# STM32WL3xx register map
File version: 1.0
Registers are 32-bit, read-write, reset 0x0 unless marked. A register's access mark holds for its fields unless they carry their own. Offsets are from the block's base; [hi:lo] are bit positions.

## MR_SUBG_GLOB_STATUS — MR_SUBG Global Status
Base 0x49000600
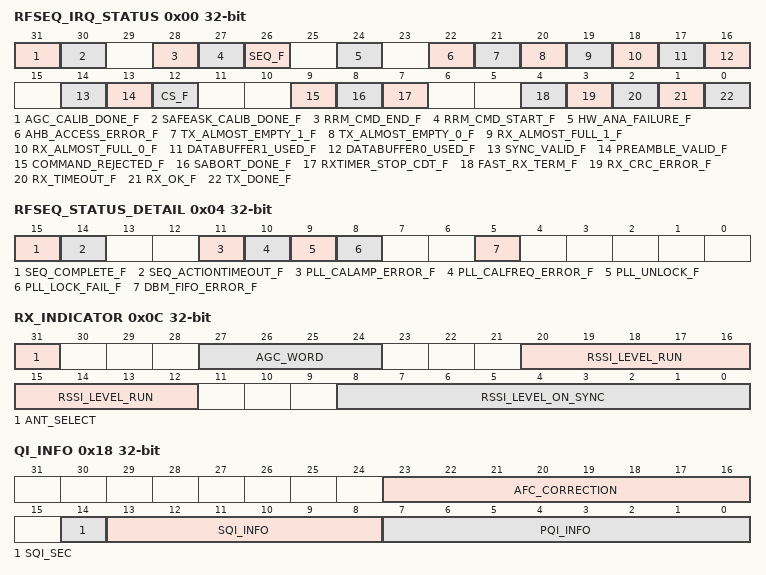
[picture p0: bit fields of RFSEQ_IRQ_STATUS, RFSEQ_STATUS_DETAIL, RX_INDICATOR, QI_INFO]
0x00 RFSEQ_IRQ_STATUS — (@ 0x00000000) RFSEQ_IRQ_STATUS register
  [31] AGC_CALIB_DONE_F, [30] SAFEASK_CALIB_DONE_F, [28] RRM_CMD_END_F, [27] RRM_CMD_START_F, [26] SEQ_F, [24] HW_ANA_FAILURE_F, [22] AHB_ACCESS_ERROR_F, [21] TX_ALMOST_EMPTY_1_F, [20] TX_ALMOST_EMPTY_0_F, [19] RX_ALMOST_FULL_1_F, [18] RX_ALMOST_FULL_0_F, [17] DATABUFFER1_USED_F, [16] DATABUFFER0_USED_F, [14] SYNC_VALID_F, [13] PREAMBLE_VALID_F, [12] CS_F, [9] COMMAND_REJECTED_F, [8] SABORT_DONE_F, [7] RXTIMER_STOP_CDT_F, [4] FAST_RX_TERM_F, [3] RX_CRC_ERROR_F, [2] RX_TIMEOUT_F, [1] RX_OK_F, [0] TX_DONE_F
0x04 RFSEQ_STATUS_DETAIL — (@ 0x00000004) RFSEQ_STATUS_DETAIL register
  [15] SEQ_COMPLETE_F, [14] SEQ_ACTIONTIMEOUT_F, [11] PLL_CALAMP_ERROR_F, [10] PLL_CALFREQ_ERROR_F, [9] PLL_UNLOCK_F, [8] PLL_LOCK_FAIL_F, [5] DBM_FIFO_ERROR_F
0x08 RADIO_FSM_INFO — (@ 0x00000008) RADIO_FSM_INFO register
  [4:0] RADIO_FSM_STATE
0x0C RX_INDICATOR — (@ 0x0000000C) RX_INDICATOR register
  [31] ANT_SELECT, [27:24] AGC_WORD, [20:12] RSSI_LEVEL_RUN, [8:0] RSSI_LEVEL_ON_SYNC
0x10 RX_INFO_REG — (@ 0x00000010) RX_INFO_REG register
  [15:0] RX_PCKTLEN_OUT
0x14 RX_CRC_REG — (@ 0x00000014) RX_CRC_REG register
  [31:0] RX_CRC_OUT
0x18 QI_INFO — (@ 0x00000018) QI_INFO register
  [23:16] AFC_CORRECTION, [14] SQI_SEC, [13:8] SQI_INFO, [7:0] PQI_INFO
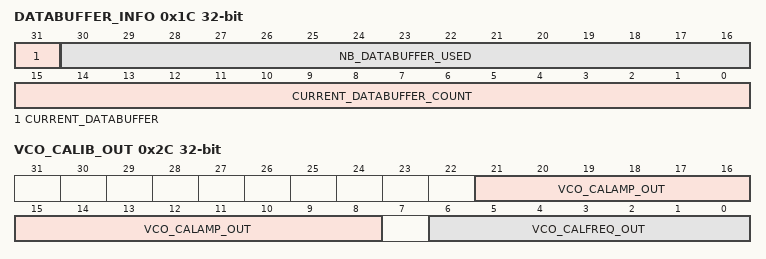
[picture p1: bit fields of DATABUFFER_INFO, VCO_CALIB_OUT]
0x1C DATABUFFER_INFO — (@ 0x0000001C) DATABUFFER_INFO register
  [31] CURRENT_DATABUFFER, [30:16] NB_DATABUFFER_USED, [15:0] CURRENT_DATABUFFER_COUNT
0x20 TIME_CAPTURE — (@ 0x00000020) TIME_CAPTURE register
0x24 IQC_CORRECTION_OUT — (@ 0x00000024) IQC_CORRECTION_OUT register
  [23:0] IQC_CORRECT_OUT
0x28 PA_SAFEASK_OUT — (@ 0x00000028) PA_SAFEASK_OUT register
  [7:0] PA_CODEMAX
0x2C VCO_CALIB_OUT — (@ 0x0000002C) VCO_CALIB_OUT register
  [21:8] VCO_CALAMP_OUT, [6:0] VCO_CALFREQ_OUT
0x30 SEQ_INFO — (@ 0x00000030) SEQ_INFO register
  [4:0] SEQ_FSM_STATE
0x34 SEQ_EVENT_STATUS — (@ 0x00000034) SEQ_EVENT_STATUS register

## MR_SUBG_GLOB_MISC — MR_SUBG Global Misc
Base 0x49000700
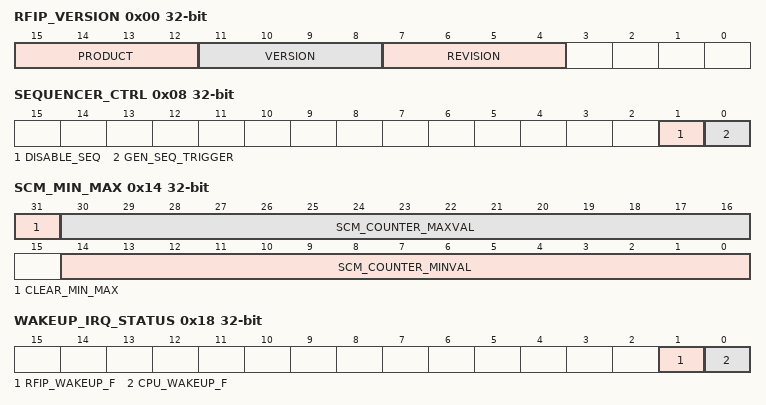
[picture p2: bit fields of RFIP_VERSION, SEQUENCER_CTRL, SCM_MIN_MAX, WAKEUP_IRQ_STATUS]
0x00 RFIP_VERSION — (@ 0x00000000) RFIP_VERSION register
  [15:12] PRODUCT, [11:8] VERSION, [7:4] REVISION
0x04 RRM_UDRA_CTRL — (@ 0x00000004) RRM_UDRA_CTRL register
  [0] RRM_CMD_REQ
0x08 SEQUENCER_CTRL — (@ 0x00000008) SEQUENCER_CTRL register
  [1] DISABLE_SEQ, [0] GEN_SEQ_TRIGGER
0x0C ABSOLUTE_TIME — (@ 0x0000000C) ABSOLUTE_TIME register
0x10 SCM_COUNTER_VAL — (@ 0x00000010) SCM_COUNTER_VAL register
  [14:0] SCM_COUNTER_CURRVAL
0x14 SCM_MIN_MAX — (@ 0x00000014) SCM_MIN_MAX register
  [31] CLEAR_MIN_MAX, [30:16] SCM_COUNTER_MAXVAL, [14:0] SCM_COUNTER_MINVAL
0x18 WAKEUP_IRQ_STATUS — (@ 0x00000018) WAKEUP_IRQ_STATUS register
  [1] RFIP_WAKEUP_F, [0] CPU_WAKEUP_F

## MR_SUBG_GLOB_RETAINED — MR_SUBG Global Retained
Base 0x49000780
0x00 RFIP_WAKEUPTIME — (@ 0x00000000) RFIP_WAKEUPTIME register
0x04 CPU_WAKEUPTIME — (@ 0x00000004) CPU_WAKEUPTIME register
  [31:1] CPU_WAKEUPTIME
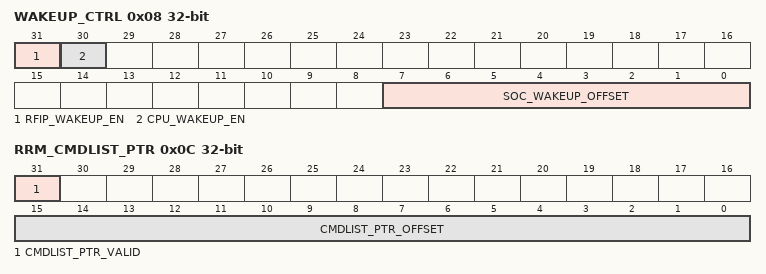
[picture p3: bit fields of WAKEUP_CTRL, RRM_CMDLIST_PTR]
0x08 WAKEUP_CTRL — (@ 0x00000008) WAKEUP_CTRL register
  [31] RFIP_WAKEUP_EN, [30] CPU_WAKEUP_EN, [7:0] SOC_WAKEUP_OFFSET
0x0C RRM_CMDLIST_PTR — (@ 0x0000000C) RRM_CMDLIST_PTR register
  [31] CMDLIST_PTR_VALID, [15:0] CMDLIST_PTR_OFFSET
0x10 SEQ_GLOBALTABLE_PTR — (@ 0x00000010) SEQ_GLOBALTABLE_PTR register
  [15:0] SEQ_GLOBALTABLE_PTR

## LPAWUR — Low Power Autonomous Wakeup Radio IP
Base 0x49001000
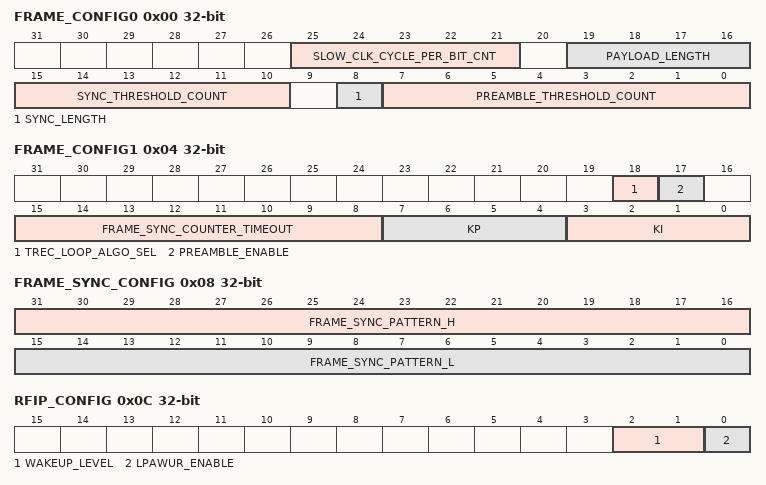
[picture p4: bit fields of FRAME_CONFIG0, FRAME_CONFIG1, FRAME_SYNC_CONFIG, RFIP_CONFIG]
0x00 FRAME_CONFIG0 — (@ 0x00000000) FRAME_CONFIG0 register
  [25:21] SLOW_CLK_CYCLE_PER_BIT_CNT, [19:16] PAYLOAD_LENGTH, [15:10] SYNC_THRESHOLD_COUNT, [8] SYNC_LENGTH, [7:0] PREAMBLE_THRESHOLD_COUNT
0x04 FRAME_CONFIG1 — (@ 0x00000004) FRAME_CONFIG1 register
  [18] TREC_LOOP_ALGO_SEL, [17] PREAMBLE_ENABLE, [15:8] FRAME_SYNC_COUNTER_TIMEOUT, [7:4] KP, [3:0] KI
0x08 FRAME_SYNC_CONFIG — (@ 0x00000008) FRAME_SYNC_CONFIG register
  [31:16] FRAME_SYNC_PATTERN_H, [15:0] FRAME_SYNC_PATTERN_L
0x0C RFIP_CONFIG — (@ 0x0000000C) RFIP_CONFIG register
  [2:1] WAKEUP_LEVEL, [0] LPAWUR_ENABLE
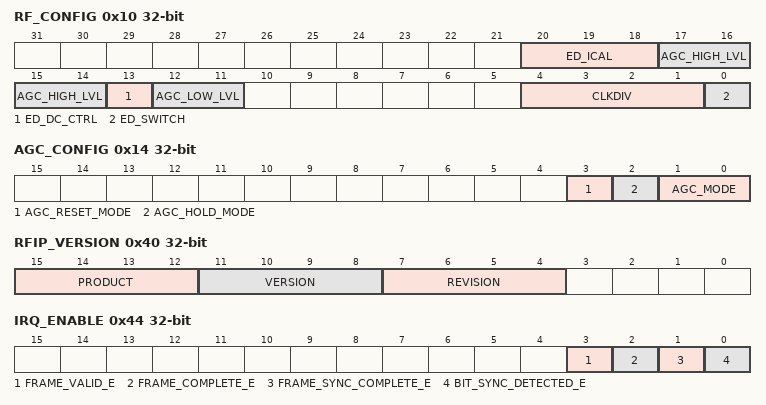
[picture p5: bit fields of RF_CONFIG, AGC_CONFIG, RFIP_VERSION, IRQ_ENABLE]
0x10 RF_CONFIG — (@ 0x00000010) RF_CONFIG register
  [20:18] ED_ICAL, [17:14] AGC_HIGH_LVL, [13] ED_DC_CTRL, [12:11] AGC_LOW_LVL, [4:1] CLKDIV, [0] ED_SWITCH
0x14 AGC_CONFIG — (@ 0x00000014) AGC_CONFIG register
  [3] AGC_RESET_MODE, [2] AGC_HOLD_MODE, [1:0] AGC_MODE
0x1C PAYLOAD_0 — (@ 0x0000001C) PAYLOAD_0 register
0x20 PAYLOAD_1 — (@ 0x00000020) PAYLOAD_1 register
0x40 RFIP_VERSION — (@ 0x00000040) RFIP_VERSION register
  [15:12] PRODUCT, [11:8] VERSION, [7:4] REVISION
0x44 IRQ_ENABLE — (@ 0x00000044) IRQ_ENABLE register
  [3] FRAME_VALID_E, [2] FRAME_COMPLETE_E, [1] FRAME_SYNC_COMPLETE_E, [0] BIT_SYNC_DETECTED_E
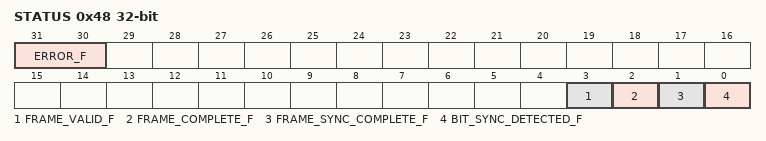
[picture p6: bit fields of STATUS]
0x48 STATUS — (@ 0x00000048) STATUS register
  [31:30] ERROR_F, [3] FRAME_VALID_F, [2] FRAME_COMPLETE_F, [1] FRAME_SYNC_COMPLETE_F, [0] BIT_SYNC_DETECTED_F
